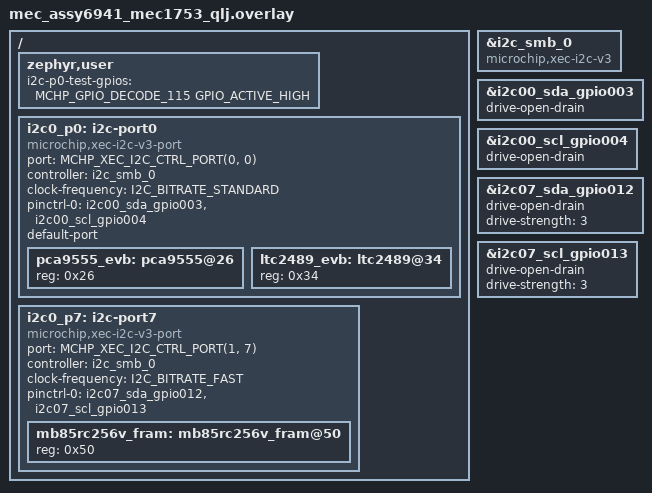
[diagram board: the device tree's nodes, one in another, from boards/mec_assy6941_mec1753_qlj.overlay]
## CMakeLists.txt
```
# Copyright (c) 2026 Microchip Technology Inc.
#
# SPDX-License-Identifier: Apache-2.0
#
cmake_minimum_required(VERSION 3.20.0)

find_package(Zephyr REQUIRED HINTS $ENV{ZEPHYR_BASE})
project(microchip_evb_xec_i2c_v3_ctrl_port_switch)

FILE(GLOB app_sources src/*.c)

target_sources(app PRIVATE ${app_sources})
```

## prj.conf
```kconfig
# Enable config log
CONFIG_STDOUT_CONSOLE=y
CONFIG_LOG=y
CONFIG_LOG_BUFFER_SIZE=8096

CONFIG_I2C=y
CONFIG_I2C_MCHP_XEC_V3_ENABLE_RECOV_COUNTERS=y

CONFIG_PM_DEVICE=y
```

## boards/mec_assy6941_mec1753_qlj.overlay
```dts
/*
 * Copyright (c) 2026 Microchip Technology Inc.
 *
 * SPDX-License-Identifier: Apache-2.0
 */

/* mec_assy6941 EVB
 *
 * Set VTR2 to +3.3V
 * J68 2x8 1-2
 *
 * I2C Port 0
 * ----------
 * JP15 3x6 Pin Mux
 * ----------------
 * JP15 7-8 GPIO004 as I2C00_SCL
 * JP15 4-5 GPIO003 as I2C00_SDA
 *
 * JP27 3x12 Pin Mux
 * -----------------
 * JP27 31-32 GPIO004 as I2C00_SCL
 * JP27 34-35 GPIO003 as I2C00_SDA
 *
 * JP70 2x17 Pull-Up Selects
 * -------------------------
 * JP70 19-20 ON enable 7.5K pull-up to VTR1
 * JP70 21-22 ON enable 7.5K pull-up to VTR1
 *
 * J12 1x6
 * ------------------------------
 *	pin 1 = I2C00_SCL/GPIO004
 *	pin 2 = GND
 *	pin 3 = I2C00_SDA/GPIO003
 *	pin 4 = GND
 *	pin 5 = VTR1
 *	pin 6 = GND
 *
 *
 * ----------------
 * I2C Port 7
 * ----------------
 * JP14 3x6
 * --------
 * 7-8, 16-17 
 *
 * JP76 2x17
 * ---------
 * 21-22 7.5K pull-up to VTR2
 * 23-24 7.5K pull-up to VTR2
 * 
 * J22 1x6
 * ------------------------------
 *	pin 1 = I2C07_SCL/GPIO013
 *	pin 2 = GND
 *	pin 3 = I2C07_SDA/GPIO012
 *	pin 4 = GND
 *	pin 5 = VTR2
 *	pin 6 = GND
 *
 */

#include <zephyr/dt-bindings/gpio/microchip-xec-gpio.h>
#include <zephyr/dt-bindings/i2c/i2c.h>
#include <zephyr/dt-bindings/i2c/mchp-xec-i2c.h>

/* I2C Controller 0 */
&i2c_smb_0 {
	compatible = "microchip,xec-i2c-v3";
	status = "okay";
	#address-cells = <1>;
	#size-cells = <0>;
};

/* Port 0 pins */
&i2c00_sda_gpio003 {
	drive-open-drain;
};

&i2c00_scl_gpio004 {
	drive-open-drain;
};

/* Port 7 pins */
&i2c07_sda_gpio012 {
	drive-open-drain;
	drive-strength = <3>;
};

&i2c07_scl_gpio013 {
	drive-open-drain;
	drive-strength = <3>;
};

/ {
	zephyr,user {
		i2c-p0-test-gpios = <MCHP_GPIO_DECODE_115 GPIO_ACTIVE_HIGH>;
	};

	/* Port 0 (default port) on I2C Controller 0 */
	i2c0_p0: i2c-port0 {
		compatible = "microchip,xec-i2c-v3-port";
		#address-cells = <1>;
		#size-cells = <0>;
		port = <MCHP_XEC_I2C_CTRL_PORT(0, 0)>;
		controller = <&i2c_smb_0>;
		clock-frequency = <I2C_BITRATE_STANDARD>;
		pinctrl-0 = <&i2c00_sda_gpio003 &i2c00_scl_gpio004>;
		pinctrl-names = "default";
		default-port;
		status = "okay";

		pca9555_evb: pca9555@26 {
			reg = <0x26>;
			status = "okay";
		};

		ltc2489_evb: ltc2489@34 {
			reg = <0x34>;
			status = "okay";
		};
	};

	/* Port 7 on I2C controller 0 */
	i2c0_p7: i2c-port7 {
		compatible = "microchip,xec-i2c-v3-port";
		#address-cells = <1>;
		#size-cells = <0>;
		port = <MCHP_XEC_I2C_CTRL_PORT(1, 7)>;
		controller = <&i2c_smb_0>;
		clock-frequency = <I2C_BITRATE_FAST>;
		pinctrl-0 = <&i2c07_sda_gpio012 &i2c07_scl_gpio013>;
		pinctrl-names = "default";
		status = "okay";

		mb85rc256v_fram: mb85rc256v_fram@50 {
			reg = <0x50>;
			#io-channels-cells = <1>;
		};
	};
};
```

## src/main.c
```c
/*
 * Copyright (c) 2026 Microchip Technology Inc.
 *
 * SPDX-License-Identifier: Apache-2.0
 */

#include <soc.h>
#include <string.h>
#include <zephyr/kernel.h>
#include <zephyr/device.h>
#include <zephyr/devicetree.h>
#include <zephyr/drivers/gpio.h>
#include <zephyr/drivers/i2c.h>
#include <zephyr/drivers/i2c/target/eeprom.h>
#include <zephyr/dt-bindings/i2c/i2c.h>
#include <zephyr/dt-bindings/i2c/mchp-xec-i2c.h>

#include <zephyr/logging/log.h>
#include <zephyr/logging/log_ctrl.h>
LOG_MODULE_REGISTER(app, CONFIG_LOG_DEFAULT_LEVEL);

#define APP_TEST_LTC2489

#define PCA9555_CMD_PORT0_IN  0
#define PCA9555_CMD_PORT1_IN  1u
#define PCA9555_CMD_PORT0_OUT 2u
#define PCA9555_CMD_PORT1_OUT 3u
#define PCA9555_CMD_PORT0_POL 4u
#define PCA9555_CMD_PORT1_POL 5u
#define PCA9555_CMD_PORT0_CFG 6u
#define PCA9555_CMD_PORT1_CFG 7u

#define LTC2489_ADC_CONV_TIME_MS 150
#define LTC2489_ADC_READ_RETRIES 10
#define LTC2489_ADC_CMD_RETRIES 10
#define LTC2489_ADC_CMD_DELAY_MS 50

#define ZEPHYR_USER_NODE DT_PATH(zephyr_user)

#define I2C_SMB_GET_DEV(nid) DEVICE_DT_GET(nid),

#define NODE_PCA9555 DT_NODELABEL(pca9555_evb)
#define NODE_LTC2489 DT_NODELABEL(ltc2489_evb)
#define NODE_FRAM    DT_NODELABEL(mb85rc256v_fram)

const struct i2c_dt_spec pca9555_spec = I2C_DT_SPEC_GET(NODE_PCA9555);
#ifdef APP_TEST_LTC2489
const struct i2c_dt_spec ltc2489_spec = I2C_DT_SPEC_GET(NODE_LTC2489);
#endif
const struct i2c_dt_spec mb_fram_spec = I2C_DT_SPEC_GET(NODE_FRAM);

static const struct device *i2c_smb_ctrls[] = {
	DT_FOREACH_STATUS_OKAY(microchip_xec_i2c_v3, I2C_SMB_GET_DEV)};

/* Ports on the controllers */
static const struct device *i2c_smb_ports[] = {
	DT_FOREACH_STATUS_OKAY(microchip_xec_i2c_v3_port, I2C_SMB_GET_DEV)};

#define I2C_MAX_MSGS    8
#define I2C_TX_BUF_SIZE 256
#define I2C_RX_BUF_SIZE 256

static struct i2c_msg msgs[I2C_MAX_MSGS];
static uint8_t i2c_tx_buf[I2C_TX_BUF_SIZE];
static uint8_t i2c_rx_buf[I2C_RX_BUF_SIZE];

static int pca9555_test1(const struct i2c_dt_spec *dts, uint8_t port, uint16_t *port_value);
#ifdef APP_TEST_LTC2489
static int ltc2489_test1(const struct i2c_dt_spec *dts, uint32_t *reading, uint32_t *cmd_attempts,
			 uint32_t *rd_attempts);
#endif
static int fram_test1(const struct i2c_dt_spec *dts);
static int fram_test2(const struct i2c_dt_spec *dts);

static volatile bool run = false;

int main(void)
{
	uint64_t test_loops = 0;
	uint64_t pca9555_errors = 0, pca9555_err_prev = 0;
	uint64_t fram_errors = 0, fram_err_prev = 0;
#ifdef APP_TEST_LTC2489
	uint64_t ltc2489_errors = 0, ltc2489_err_prev = 0;
	uint32_t adc_reading = 0, adc_cmd_attempts = 0, adc_rd_attempts = 0;
#endif
	int ctrl_ready_count = 0;
	int port_ready_count = 0;
	int rc = 0;

	memset((void *)msgs, 0, sizeof(msgs));
	memset(i2c_tx_buf, 0x55, I2C_TX_BUF_SIZE);
	memset(i2c_rx_buf, 0xAA, I2C_RX_BUF_SIZE);

	for (size_t i = 0; i < ARRAY_SIZE(i2c_smb_ctrls); i++) {
		const struct device *ctrl_dev = i2c_smb_ctrls[i];

		if (ctrl_dev == NULL) {
			continue;
		}

		if (device_is_ready(ctrl_dev)) {
			ctrl_ready_count++;
			LOG_INF("I2C Controller device %s is ready", ctrl_dev->name);
		} else {
			LOG_ERR("I2C Controller device %s is NOT ready", ctrl_dev->name);
		}
	}

	for (size_t i = 0; i < ARRAY_SIZE(i2c_smb_ports); i++) {
		const struct device *port_dev = i2c_smb_ports[i];

		if (port_dev == NULL) {
			continue;
		}

		if (device_is_ready(port_dev)) {
			port_ready_count++;
			LOG_INF("I2C Port device %s is ready", port_dev->name);
		} else {
			LOG_ERR("I2C Port device %s is NOT ready", port_dev->name);
		}
	}

	log_flush();

	if ((ctrl_ready_count > 0) && (port_ready_count > 0)) {
		LOG_INF("Enter test loop");
		run = true;
	} else {
		LOG_ERR("ctrl_ready_count = %u port_ready_count = %u",
		        ctrl_ready_count, port_ready_count);
	}

	log_flush();

	while (run) {
		test_loops++;

		rc = pca9555_test1(&pca9555_spec, PCA9555_CMD_PORT0_IN, NULL);
		if (rc != 0) {
			pca9555_errors++;
		}

		rc = fram_test1(&mb_fram_spec);
		if (rc != 0) {
			fram_errors++;
		}

		rc = pca9555_test1(&pca9555_spec, PCA9555_CMD_PORT1_IN, NULL);
		if (rc != 0) {
			pca9555_errors++;
		}

		rc = fram_test2(&mb_fram_spec);
		if (rc != 0) {
			fram_errors++;
		}

#ifdef APP_TEST_LTC2489
		adc_reading = 0xDEADBEEFU;
		adc_cmd_attempts = 0;
		adc_rd_attempts = 0;

		rc = ltc2489_test1(&ltc2489_spec, &adc_reading, &adc_cmd_attempts,
				   &adc_rd_attempts);
		if (rc != 0) {
			ltc2489_errors++;
		}
#endif
		if (pca9555_errors != pca9555_err_prev) {
			pca9555_err_prev = pca9555_errors;
			LOG_ERR("PCA9555 errors change 0x%0llx", pca9555_errors); 
		}

		if (fram_err_prev != fram_errors) {
			fram_err_prev = fram_errors;
			LOG_ERR("FRAM errors change 0x%0llx", fram_errors); 
		}

#ifdef APP_TEST_LTC2489
		if (ltc2489_err_prev != ltc2489_errors) {
			ltc2489_err_prev = ltc2489_errors;
			LOG_ERR("LTC2489 errors change 0x%0llx", ltc2489_errors); 
		}

		LOG_INF("LTC2489 reading = 0x%08x, cmd attempts = %u rd attempts = %u",
			adc_reading, adc_cmd_attempts, adc_rd_attempts);
#endif
	};

	LOG_INF("Test loop exit: loops = %llu", test_loops);
	LOG_INF("Program End");
	log_flush();

	return 0;
}

static int pca9555_test1(const struct i2c_dt_spec *dts, uint8_t port, uint16_t *port_value)
{
	int rc = -ENOTSUP;

	if (dts == NULL) {
		return -EINVAL;
	}

	memset(i2c_tx_buf, 0x55, sizeof(i2c_tx_buf));
	memset(i2c_rx_buf, 0xAA, sizeof(i2c_rx_buf));

	i2c_tx_buf[0] = port;

	rc = i2c_write_read_dt(dts, i2c_tx_buf, 1U, i2c_rx_buf, 2U);
	if (rc != 0) {
		return rc;
	}

	if (port_value != NULL) {
		*port_value = ((uint16_t)i2c_rx_buf[1] << 8) | i2c_rx_buf[0];
	}

	return rc;
}

#ifdef APP_TEST_LTC2489
/* LTC2489 is a troublesome device
 * It will NAK its address if it is busy. Power on reset causes it to be busy.
 */
static int ltc2489_test1(const struct i2c_dt_spec *dts, uint32_t *reading, uint32_t *cmd_attempts,
			 uint32_t *rd_attempts)
{
	int rc = -ENOTSUP;
	uint32_t adc_read_attempts = 0, n = 0;
	uint32_t readval = 0xff000000U;

	if (dts == NULL) {
		return -EINVAL;
	}

	while (n < LTC2489_ADC_CMD_RETRIES) {
		n++;

		/* Read ADC channel 0. Selecting the channel initiates a reading */
		i2c_tx_buf[0] = 0xb0U; /* 1011_0000 selects channel 0 as single ended */

		rc = i2c_write_dt(dts, i2c_tx_buf, 1U);
		if (rc == 0) {
			break;
		}

		k_sleep(K_MSEC(LTC2489_ADC_CMD_DELAY_MS));
	}

	if (cmd_attempts != NULL) {
		*cmd_attempts = n;
	}

	/* LTC2489 will NAK while it is converting */
	k_sleep(K_MSEC(LTC2489_ADC_CONV_TIME_MS));

	do {
		adc_read_attempts++;

		i2c_rx_buf[0] = 0x55U;
		i2c_rx_buf[1] = 0x55U;
		i2c_rx_buf[2] = 0x55U;

		rc = i2c_read_dt(dts, i2c_rx_buf, 3U);
		if (rc == 0) {
			break;
		}
	} while (adc_read_attempts <= LTC2489_ADC_READ_RETRIES);

	if (rd_attempts != NULL) {
		*rd_attempts = adc_read_attempts;
	}

	if (rc == 0) {
		readval = ((uint32_t)i2c_rx_buf[0] + ((uint32_t)i2c_rx_buf[1] << 8) +
			   ((uint32_t)i2c_rx_buf[2] << 16));
	}

	if (reading != NULL) {
		*reading = readval;
	}

	return rc;
}
#endif

static int fram_test1(const struct i2c_dt_spec *dts)
{
	int rc = -ENOTSUP;

	if (dts == NULL) {
		return -EINVAL;
	}

	memset(i2c_tx_buf, 0x55, sizeof(i2c_tx_buf));
	memset(i2c_rx_buf, 0xAA, sizeof(i2c_rx_buf));

	i2c_tx_buf[0] = 0x43U;
	i2c_tx_buf[1] = 0x21U;
	i2c_tx_buf[2] = 0x01U;
	i2c_tx_buf[3] = 0x02U;
	i2c_tx_buf[4] = 0x03U;
	i2c_tx_buf[5] = 0x04U;

	rc = i2c_write_dt(dts, i2c_tx_buf, 4U);
	if (rc != 0) {
		return rc;
	}

	i2c_tx_buf[0] = 0x43U;
	i2c_tx_buf[1] = 0x21U;

	rc = i2c_write_read_dt(dts, i2c_tx_buf, 2U, i2c_rx_buf, 2U);
	if (rc != 0) {
		return rc;
	}

	rc = memcmp(&i2c_tx_buf[2], i2c_rx_buf, 2U);
	if (rc != 0) {
		rc = -EPERM;
	}

	return rc;
}

static int fram_test2(const struct i2c_dt_spec *dts)
{
	int rc = -ENOTSUP;

	if (dts == NULL) {
		return -EINVAL;
	}

	memset(i2c_tx_buf, 0x55, sizeof(i2c_tx_buf));
	memset(i2c_rx_buf, 0xAA, sizeof(i2c_rx_buf));

	i2c_tx_buf[0] = 0x12U;
	i2c_tx_buf[1] = 0x30U;
	for (uint32_t i = 0; i < 32U; i++) {
		i2c_tx_buf[i + 2U] = (uint8_t)(i % 256U);
	}

	rc = i2c_write_dt(dts, i2c_tx_buf, 34U);
	if (rc != 0) {
		return rc;
	}

	i2c_tx_buf[0] = 0x12U;
	i2c_tx_buf[1] = 0x30U;

	rc = i2c_write_read_dt(dts, i2c_tx_buf, 2U, i2c_rx_buf, 32U);
	if (rc != 0) {
		return rc;
	}

	rc = memcmp(&i2c_tx_buf[2], i2c_rx_buf, 32U);
	if (rc != 0) {
		rc = -EPERM;
	}

	return rc;
}
```
